# R7FA6M3AH register map
Vendor: Renesas; Series: RA6; File version: 1.2
CPU: CM4 r0p1, little endian, MPU, FPU, VTOR, 4 interrupt priority bits
Registers are 32-bit, read-write, reset 0x0 unless marked. A register's access mark holds for its fields unless they carry their own. Offsets are from the block's base; [hi:lo] are bit positions; {n}, {i} and the like mark numbered series; 'fields as' and 'values as' point back to an identical list.

## USBHS — USB 2.0 High,Speed Module
Base 0x40060000
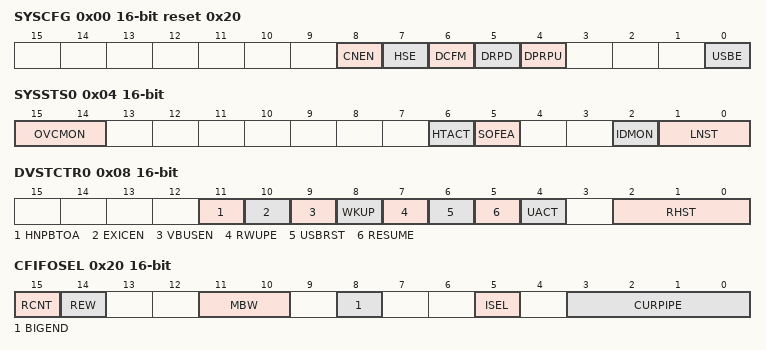
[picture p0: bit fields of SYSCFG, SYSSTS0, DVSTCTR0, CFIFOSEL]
0x00 SYSCFG 16-bit reset 0x20 — System Configuration Control Register
  [8] CNEN — Single End Receiver Enable
  [7] HSE — High,Speed Operation Enable
  [6] DCFM — Controller Function Select
  [5] DRPD — D+/D- Line Resistor Control
  [4] DPRPU — D+ Line Resistor Control
  [0] USBE — USB Operation Enable
0x02 BUSWAIT 16-bit reset 0xF — CPU Bus Wait Register
  [3:0] BWAIT — CPU Bus Access Wait Specification BWAIT waits (BWAIT+2 access cycles)
0x04 SYSSTS0 16-bit ro (reset mask 0x60) — System Configuration Status Register
  [15:14] OVCMON — External USB1_OVRCURA/USB1_OVRCURB Input Pin MonitorThe OCVMON[1] bit indicates the status of the USBHS_OVRCURA pin. The OCVMON[0] bit indicates the status of the USBHS_OVRCURB pin.
  [6] HTACT — Host Sequencer Status Monitor
  [5] SOFEA — SOF Active Monitor While Host Controller Function is Selected.
  [2] IDMON — ID0 Pin Monitor
  [1:0] LNST — USB Data Line Status Monitor
0x06 PLLSTA 16-bit ro — PLL Status Register
  [0] PLLLOCK — PLL Lock Flag
0x08 DVSTCTR0 16-bit — Device State Control Register 0
  [11] HNPBTOA — Host Negotiation Protocol (HNP) Control Use this bit when switching from device B to device A in OTGmode. If the HNPBTOA bit is 1, the internal function controlremains in the Suspend state until the HNP processing endseven if SYSCFG.DPRPU = 0 or SYSCFG.DCFM = 1 is set.
  [10] EXICEN — USBHS_EXICEN Output Pin Control
  [9] VBUSEN — USBHS_VBUSEN Output Pin Control
  [8] WKUP — Remote Wakeup Output for the Device Controller Operation
  [7] RWUPE — Remote Wakeup Detection Enable for the Host Controller Operation
  [6] USBRST — USB Bus Reset Output for the Host Controller Operation
  [5] RESUME — Resume Signal Output for the Host Controller Operation
  [4] UACT — USB Bus Operation Enable for the Host Controller Operation
  [2:0] RHST ro — USB Bus Reset Status
0x0C TESTMODE 16-bit — USB Test Mode Register
  [3:0] UTST — Test Mode
0x14 CFIFO — CFIFO Port Register
  [31:0] FIFOPORT — FIFO Port.Read receive data from the FIFO buffer or write transmit data to the FIFO buffer by accessing these bits.
0x14 CFIFOL 16-bit (alternate view of CFIFO) — CFIFO Port Register L
0x14 CFIFOLL 8-bit (alternate view of CFIFOL) — CFIFO Port Register LL
0x16 CFIFOH 16-bit (alternate view of CFIFO) — CFIFO Port Register H
0x17 CFIFOHH 8-bit (alternate view of CFIFOH) — CFIFO Port Register HH
0x18 D0FIFO — D0FIFO Port Register
  [31:0] FIFOPORT — FIFO Port Read receive data from the FIFO buffer or write transmit data to the FIFO buffer by accessing these bits.
0x18 D0FIFOL 16-bit (alternate view of D0FIFO) — D0FIFO Port Register L
0x18 D0FIFOLL 8-bit (alternate view of D0FIFOL) — D0FIFO Port Register LL
0x1A D0FIFOH 16-bit (alternate view of D0FIFO) — D0FIFO Port Register H
0x1B D0FIFOHH 8-bit (alternate view of D0FIFOH) — D0FIFO Port Register HH
0x1C D1FIFO — D1FIFO Port Register
  [31:0] FIFOPORT — FIFO PortRead receive data from the FIFO buffer or write transmit data to the FIFO buffer by accessing these bits.
0x1C D1FIFOL 16-bit (alternate view of D1FIFO) — D1FIFO Port Register L
0x1C D1FIFOLL 8-bit (alternate view of D1FIFOL) — D1FIFO Port Register LL
0x1E D1FIFOH 16-bit (alternate view of D1FIFO) — D1FIFO Port Register H
0x1F D1FIFOHH 8-bit (alternate view of D1FIFOH) — D1FIFO Port Register HH
0x20 CFIFOSEL 16-bit — CFIFO Port Select Register
  [15] RCNT — Read Count Mode
  [14] REW wo — Buffer Pointer Rewind
  [11:10] MBW — CFIFO Port Access Bit Width
  [8] BIGEND — FIFO Port Endian Control
  [5] ISEL — FIFO Port Access Direction when DCP is Selected
  [3:0] CURPIPE — FIFO Port Access Pipe Specification
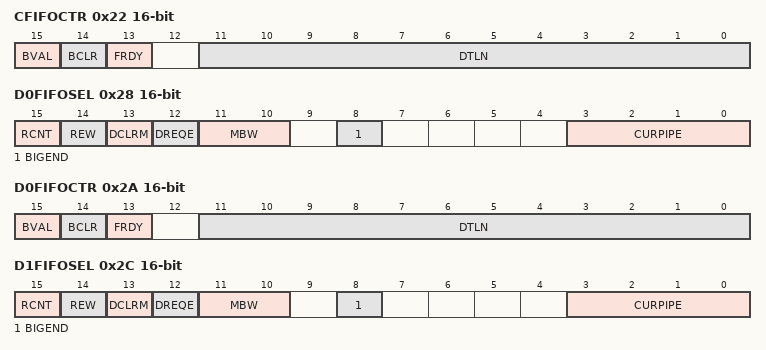
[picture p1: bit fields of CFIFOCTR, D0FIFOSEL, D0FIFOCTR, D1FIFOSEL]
0x22 CFIFOCTR 16-bit — CFIFO Port Control Register
  [15] BVAL — Buffer Memory Valid Flag
  [14] BCLR wo — CPU Buffer Clear
  [13] FRDY ro — FIFO Port ReadyIndicates whether the FIFO port can be accessed.
  [11:0] DTLN ro — Receive Data Length.Indicates the length of the receive data.
0x28 D0FIFOSEL 16-bit — D0FIFO Port Select Register
  [15] RCNT — Read Count Mode
  [14] REW wo — Buffer Pointer Rewind
  [13] DCLRM — Auto Buffer Memory Clear Mode Accessed after Specified Pipe Data is Read
  [12] DREQE — UCL_Dx_DREQ Signal Output Enable
  [11:10] MBW — FIFO Port Access Bit Width
  [8] BIGEND — FIFO Port Endian Control
  [3:0] CURPIPE — FIFO Port Access Pipe Specification
0x2A D0FIFOCTR 16-bit — D0FIFO Port Control Register
  fields as CFIFOCTR
0x2C D1FIFOSEL 16-bit — D1FIFO Port Select Register
  fields as D0FIFOSEL
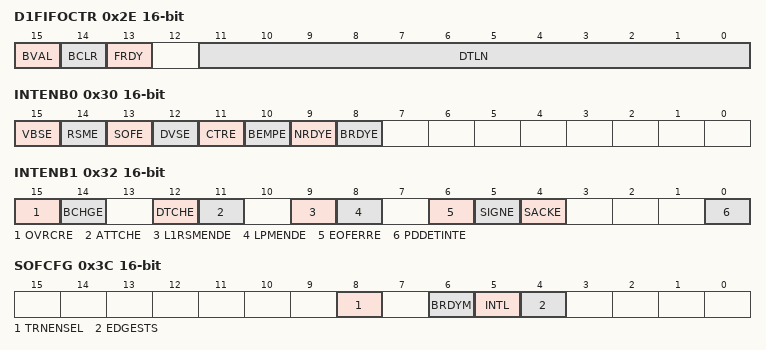
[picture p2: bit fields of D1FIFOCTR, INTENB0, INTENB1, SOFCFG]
0x2E D1FIFOCTR 16-bit — D1FIFO Port Control Register
  fields as CFIFOCTR
0x30 INTENB0 16-bit — Interrupt Enable Register 0
  [15] VBSE — VBUS Interrupt Enable
  [14] RSME — Resume Interrupt Enable
  [13] SOFE — Frame Number Update Interrupt Enable
  [12] DVSE — Device State Transition Interrupt Enable
  [11] CTRE — Control Transfer Stage Transition Interrupt Enable
  [10] BEMPE — Buffer Empty Interrupt Enable
  [9] NRDYE — Buffer Not Ready Response Interrupt Enable
  [8] BRDYE — Buffer Ready Interrupt Enable
0x32 INTENB1 16-bit — Interrupt Enable Register 1
  [15] OVRCRE — OVRCRE Interrupt Enable
  [14] BCHGE — USB Bus Change Interrupt Enable
  [12] DTCHE — Disconnection Detection Interrupt Enable
  [11] ATTCHE — Connection Detection Interrupt Enable
  [9] L1RSMENDE — L1 Resume End Interrupt Enable
  [8] LPMENDE — LPM Transaction End Interrupt Enable
  [6] EOFERRE — EOF Error Detection Interrupt Enable
  [5] SIGNE — Setup Transaction Error Interrupt Enable
  [4] SACKE — Setup Transaction Normal Response Interrupt Enable
  [0] PDDETINTE — PDDETINT Detection Interrupt Enable
0x36 BRDYENB 16-bit — BRDY Interrupt Enable Register
  [9:0] PIPEBRDYE — BRDY Interrupt Enable for Each Pipe
0x38 NRDYENB 16-bit — NRDY Interrupt Enable Register
  [9:0] PIPENRDYE — NRDY Interrupt Enable for Each Pipe
0x3A BEMPENB 16-bit — BEMP Interrupt Enable Register
  [9:0] PIPEBEMPE — BEMP Interrupt Enable for Each Pipe
0x3C SOFCFG 16-bit — SOF Pin Configuration Register
  [8] TRNENSEL — Transaction,Enabled Time Select.The transfer efficiency can be improved by setting this bit to 1 if no low,speed device is connected directly or via FS,HUB to the USB port.
  [6] BRDYM — PIPEBRDY Interrupt Status Clear Timing.This bit can be set only in the initial setting (before communications).The setting cannot be changed once communication starts.
  [5] INTL — Interrupt Output Sense Select
  [4] EDGESTS ro — Interrupt Edge Processing Status Monitor
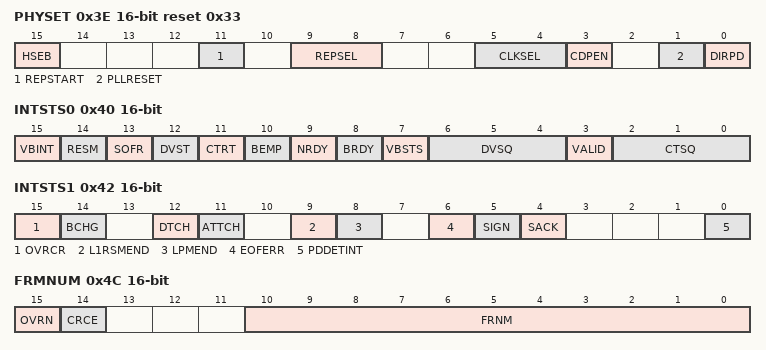
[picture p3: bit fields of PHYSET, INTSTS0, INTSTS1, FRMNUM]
0x3E PHYSET 16-bit reset 0x33 (reset mask 0xB3B) — PHY Setting Register
  [15] HSEB — CL,Only Mode
  [11] REPSTART — Forcibly Start Terminating Resistance Adjustment
  [9:8] REPSEL — Terminating Resistance Adjustment Cycle
  [5:4] CLKSEL — Input System Clock Frequency
  [3] CDPEN — Charging Downstream Port Enable
  [1] PLLRESET — PLL Reset Control
  [0] DIRPD — Power,Down Control
0x40 INTSTS0 16-bit (reset mask 0xFF7F) — Interrupt Status Register 0
  [15] VBINT — VBUS Interrupt Status
  [14] RESM — Resume Interrupt Status
  [13] SOFR — Frame Number Refresh Interrupt Status
  [12] DVST — Device State Transition Interrupt Status
  [11] CTRT — Control Transfer Stage Transition Interrupt Status
  [10] BEMP ro — Buffer Empty Interrupt Status
  [9] NRDY ro — Buffer Not Ready Interrupt Status
  [8] BRDY ro — Buffer Ready Interrupt Status
  [7] VBSTS ro — VBUS Input Status
  [6:4] DVSQ ro — Device State
  [3] VALID — USB Request Reception
  [2:0] CTSQ ro — Control Transfer Stage
0x42 INTSTS1 16-bit — Interrupt Status Register 1
  [15] OVRCR write-0-clears read-modifies — Overcurrent Interrupt Status
  [14] BCHG write-0-clears read-modifies — USB Bus Change Interrupt Status
  [12] DTCH write-0-clears read-modifies — USB Disconnection Detection Interrupt Status
  [11] ATTCH write-0-clears read-modifies — USB Connection Detection Interrupt Status
  [9] L1RSMEND write-0-clears read-modifies — L1 Resume End Interrupt Status
  [8] LPMEND write-0-clears read-modifies — LPM Transaction End Interrupt Status
  [6] EOFERR write-0-clears read-modifies — EOF Error Detection Interrupt Status
  [5] SIGN write-0-clears read-modifies — Setup Transaction Error Interrupt Status
  [4] SACK write-0-clears read-modifies — Setup Transaction Normal Response Interrupt Status
  [0] PDDETINT write-0-clears read-modifies — PDDET Detection Interrupt Status
0x46 BRDYSTS 16-bit — BRDY Interrupt Status Register
  [9:0] PIPEBRDY — BRDY Interrupt Status for Each Pipe
0x48 NRDYSTS 16-bit — NRDY Interrupt Status Register
  [9:0] PIPENRDY — NRDY Interrupt Status for Each Pipe
0x4A BEMPSTS 16-bit — BEMP Interrupt Status Register
  [9:0] PIPEBEMP — BEMP Interrupt Status for Each Pipe
0x4C FRMNUM 16-bit — Frame Number Register
  [15] OVRN — Overrun/Underrun Detection Status
  [14] CRCE — CRC Error Detection Status
  [10:0] FRNM ro — Frame Number.Indicate the latest frame number.
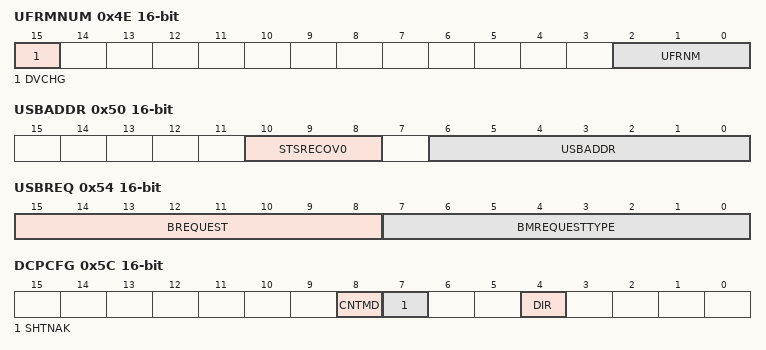
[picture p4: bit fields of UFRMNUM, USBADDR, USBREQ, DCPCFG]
0x4E UFRMNUM 16-bit — uFrame Number Register
  [15] DVCHG — Device State Change
  [2:0] UFRNM ro — MicroframeIndicate the microframe number.
0x50 USBADDR 16-bit — USB Address Register
  [10:8] STSRECOV0 — Status Recovery
  [6:0] USBADDR ro — USB Address In device controller mode, these flags indicate the USB address assigned by the host when the USBHS processed the SET_ADDRESS request successfully.
0x54 USBREQ 16-bit — USB Request Type Register
  [15:8] BREQUEST — USB request bRequest value Finction controller selected : read,only Host controller selected : read,write
  [7:0] BMREQUESTTYPE — USB request bmRequestType value Finction controller selected : read,only Host controller selected : read,write
0x56 USBVAL 16-bit — USB Request Value Register
  [15:0] WVALUE — Value of USB request wValue Finction controller selected : read,only Host controller selected : read,write
0x58 USBINDX 16-bit — USB Request Index Register
  [15:0] WINDEX — Value of USB request wIndex Finction controller selected : read,only Host controller selected : read,write
0x5A USBLENG 16-bit — USB Request Length Register
  [15:0] WLENGTH — Value of USB request wLength Finction controller selected : read,only Host controller selected : read,write
0x5C DCPCFG 16-bit — DCP Configuration Register
  [8] CNTMD — Continuous Transfer Mode
  [7] SHTNAK — Pipe Blocking on End of Transfer
  [4] DIR — Transfer Direction
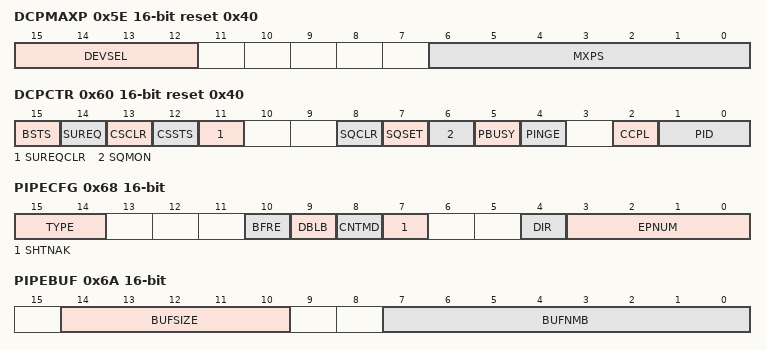
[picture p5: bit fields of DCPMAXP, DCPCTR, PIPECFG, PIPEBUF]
0x5E DCPMAXP 16-bit reset 0x40 — DCP Maximum Packet Size Register
  [15:12] DEVSEL — Device SelectThese bits specify the address of the destination function device for control transfer when the host controller function is selected.
  [6:0] MXPS — Maximum Packet SizeThese bits specify the maximum data payload (maximum packet size) for the DCP.
0x60 DCPCTR 16-bit reset 0x40 (reset mask 0xF1F7) — DCP Control Register
  [15] BSTS ro — Buffer Status
  [14] SUREQ — SETUP Token Transmission
  [13] CSCLR — Split Transaction CSPLIT Status Clear
  [12] CSSTS ro — Split Transaction COMPLETE SPLIT(CSPLIT) Status
  [11] SUREQCLR — SUREQ Bit Clear
  [8] SQCLR — Toggle Bit Clear
  [7] SQSET — Toggle Bit Set
  [6] SQMON ro — Sequence Toggle Bit Monitor
  [5] PBUSY ro — Pipe Busy
  [4] PINGE — PING Token Issue Enable
  [2] CCPL — Control Transfer End Enable
  [1:0] PID — Response PID
0x64 PIPESEL 16-bit — Pipe Window Select Register
  [3:0] PIPESEL — Pipe Window SelectThese bits specify the pipe for registers at addresses 68H to 6EH.
0x68 PIPECFG 16-bit — Pipe Configuration Register
  [15:14] TYPE — Transfer Type
  [10] BFRE — BRDY Interrupt Operation Specification
  [9] DBLB — Double Buffer Mode
  [8] CNTMD — Continuous Transfer Mode
  [7] SHTNAK — Pipe Disabled at End of Transfer
  [4] DIR — Transfer Direction
  [3:0] EPNUM — Endpoint Number
0x6A PIPEBUF 16-bit — Pipe Buffer Register
  [14:10] BUFSIZE — Buffer Size 00h: 64 bytes 01h: 128 bytes : 1Fh: 2 Kbytes
  [7:0] BUFNMB range 0x04..0x87 — Buffer NumberThese bits specify the FIFO buffer number of the selected pipe (04h to 87h).
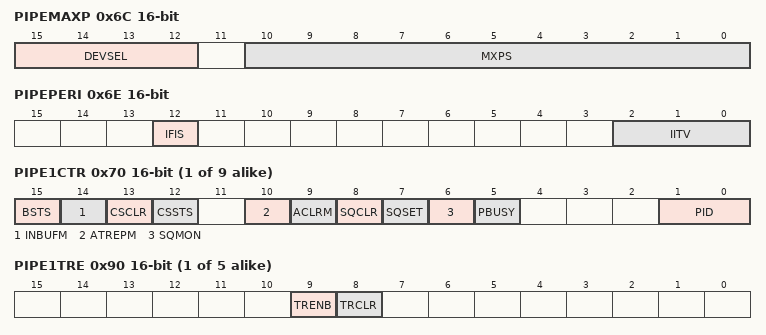
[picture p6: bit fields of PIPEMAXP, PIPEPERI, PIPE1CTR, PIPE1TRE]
0x6C PIPEMAXP 16-bit — Pipe Maximum Packet Size Register
  [15:12] DEVSEL range 0x0..0xA — Device SelectThese bits specify the address of the peripheral device when the host controller function is selected.
  [10:0] MXPS range 0x01..0x40 — Maximum Packet SizeThese bits specify the maximum data payload (maximum packet size) for the selected pipe.A size of 1h to 40h bytes can be set for PIPE6 to PIPE9.
0x6E PIPEPERI 16-bit — Pipe Cycle Control Register
  [12] IFIS — Isochronous IN Buffer Flush
  [2:0] IITV — Interval Error Detection IntervalThese bits specify the transfer interval timing for the selected pipe as n,th power of 2 of the frame timing.
{0x6E+2i} PIPE{i}CTR (i=1..9) 16-bit — PIPE Control Register
  [15] BSTS ro — Buffer StatusThis bit indicates the FIFO buffer status for the relevant pipe.
  [14] INBUFM ro — Transmit Buffer MonitorThis bit indicates the FIFO buffer status for the relevant pipe in the transmitting direction.
  [13] CSCLR — CSPLIT Status ClearSet this bit to 1 when clearing the CSSTS bit of the relevant pipe
  [12] CSSTS ro — CSSTS StatusThis bit indicates the CSPLIT status of Split Transaction of the relevant pipe
  [10] ATREPM — Auto Response ModeThis bit enables or disables auto response mode for the relevant pipe.
  [9] ACLRM — Auto Buffer Clear ModeThis bit enables or disables auto buffer clear mode for the relevant pipe
  [8] SQCLR — Toggle Bit ClearThis bit is set to 1 when the expected value of the sequence toggle bit for the next transaction of the relevant pipe is cleared to DATA0
  [7] SQSET — Toggle Bit SetThis bit is set to 1 when the expected value of the sequence toggle bit for the next transaction of the relevant pipe is set for DATA1
  [6] SQMON ro — Toggle Bit ConfirmationThis bit indicates the expected value of the sequence toggle bit for the next transaction of the relevant pipe
  [5] PBUSY ro — Pipe BusyThis bit indicates whether the relevant pipe is being used for the USB bus
  [1:0] PID — Response PIDThese bits specify the response type for the next transaction of the relevant pipe.
{0x8C+4i} PIPE{i}TRE (i=1..5) 16-bit — PIPE Transaction Counter Enable Register
  [9] TRENB — Transaction Counter EnableEnables or disables the transaction counter function.
  [8] TRCLR — Transaction Counter ClearSetting this bit to 1 allows clearing the transaction counter to 0.
{0x8E+4i} PIPE{i}TRN (i=1..5) 16-bit — PIPE Transaction Counter Register
  [15:0] TRNCNT — Transaction CounterWhen writing to: Specify the number of total packets (number of transactions) to be received by the relevant PIPE.When read from: When TRENB = 0: Indicate the specified number of transactions.When TRENB = 1: Indicate the number of currently counted transactions.
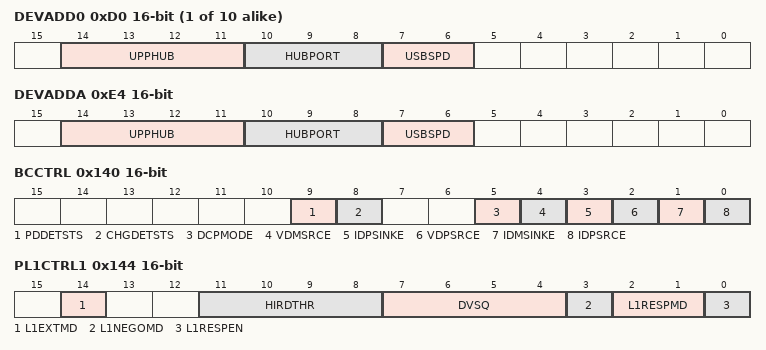
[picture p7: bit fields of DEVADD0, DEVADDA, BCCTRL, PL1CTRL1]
{0xD0+2i} DEVADD{i} (i=0..9) 16-bit — Device Address Configuration Register
  [14:11] UPPHUB range 0x0000..0x1010 — Communication Target Connecting Hub Register
  [10:8] HUBPORT — Communication Target Connecting Hub Port
  [7:6] USBSPD — Transfer Speed of Communication Target Device
0xE4 DEVADDA 16-bit — Device Address Configuration Register A
  fields as DEVADD0
0x100 LPCTRL 16-bit — Low Power Control Register
  [7] HWUPM — Resume Return Mode Setting
0x102 LPSTS 16-bit — Low Power Status Register
  [14] SUSPENDM — UTMI SuspendM Control
0x140 BCCTRL 16-bit — Battery Charging Control Register
  [9] PDDETSTS ro — PDDET Status
  [8] CHGDETSTS ro — CHGDET Status
  [5] DCPMODE — DCP Mode Control
  [4] VDMSRCE — VDMSRC Control
  [3] IDPSINKE — IDPSINK Control
  [2] VDPSRCE — VDPSRC Control
  [1] IDMSINKE — IDMSINK Control
  [0] IDPSRCE — IDPSRC Control
0x144 PL1CTRL1 16-bit — Function L1 Control Register 1
  [14] L1EXTMD — PHY Control Mode at L1 Return
  [11:8] HIRDTHR — L1 Response Negotiation Threshold ValueHIRD threshold value used for L1NEGOMD.The format is the same as the HIRD field in HL1CTRL.
  [7:4] DVSQ ro — DVSQ Extension.DVSQ[3] is Mirror of DVSQ[2:0] in INTSTS0.Indicates the L1 state together with the device state bits DVSQ[2:0].
  [3] L1NEGOMD — L1 Response Negotiation Control.NOTE: This bit is valid only when the L1RESPMD[1:0] value is 2'b11.
  [2:1] L1RESPMD — L1 Response Mode
  [0] L1RESPEN — L1 Response Enable
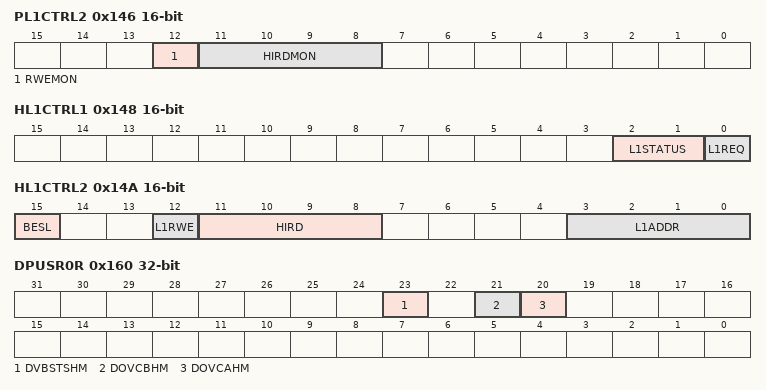
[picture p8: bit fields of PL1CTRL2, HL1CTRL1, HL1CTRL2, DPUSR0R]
0x146 PL1CTRL2 16-bit — Function L1 Control Register 2
  [12] RWEMON — RWE Value Monitor
  [11:8] HIRDMON — HIRD Value Monitor
0x148 HL1CTRL1 16-bit — Host L1 Control Register 1
  [2:1] L1STATUS ro — L1 Request Completion Status
  [0] L1REQ — L1 Transition Request
0x14A HL1CTRL2 16-bit — Host L1 Control Register 2
  [15] BESL — BESL & Alternate HIRDThis bit selects the K,State drive period at the time of L1 Resume.
  [12] L1RWE — LPM Token L1 RemoteWake EnableThese bits specify the value to be set in the RWE field of LPM token.
  [11:8] HIRD — LPM Token HIRD
  [3:0] L1ADDR — LPM Token DeviceAddressThese bits specify the value to be set in the ADDR field of LPM token.
0x160 DPUSR0R ro (reset mask 0xFF4FFFFF) — Deep Standby USB Transceiver Control/Pin Monitor Register
  [23] DVBSTSHM — VBUS InputIndicates VBUS input signal on the HS side of USB port.
  [21] DOVCBHM — OVRCURB InputIndicates OVRCURB input signal on the HS side of USB port.
  [20] DOVCAHM — OVRCURA InputIndicates OVRCURA input signal on the HS side of USB port.
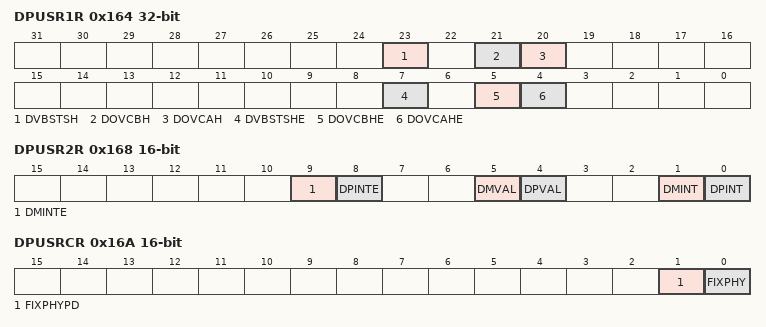
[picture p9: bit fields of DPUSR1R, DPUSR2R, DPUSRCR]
0x164 DPUSR1R — Deep Standby USB Suspend/Resume Interrupt Register
  [23] DVBSTSH ro — Indication of Return from VBUS Interrupt Source
  [21] DOVCBH ro — Indication of Return from OVRCURB Interrupt Source
  [20] DOVCAH ro — Indication of Return from OVRCURA Interrupt Source
  [7] DVBSTSHE — VBUS Interrupt Enable/Clear
  [5] DOVCBHE — OVRCURB Interrupt Enable Clear
  [4] DOVCAHE — OVRCURA Interrupt Enable Clear
0x168 DPUSR2R 16-bit — Deep Standby USB Suspend/Resume Interrupt Register
  [9] DMINTE — DM Interrupt Enable Clear
  [8] DPINTE — DP Interrupt Enable Clear
  [5] DMVAL ro — DM InputIndicates DM input signal on the HS side of USB port.
  [4] DPVAL ro — DP InputIndicates DP input signal on the HS side of USB port.
  [1] DMINT ro — Indication of Return from DM Interrupt Source
  [0] DPINT ro — Indication of Return from DP Interrupt Source
0x16A DPUSRCR 16-bit — Deep Standby USB Suspend/Resume Command Register
  [1] FIXPHYPD — USB Transceiver Control Fix for PLL
  [0] FIXPHY — USB Transceiver Control Fix
